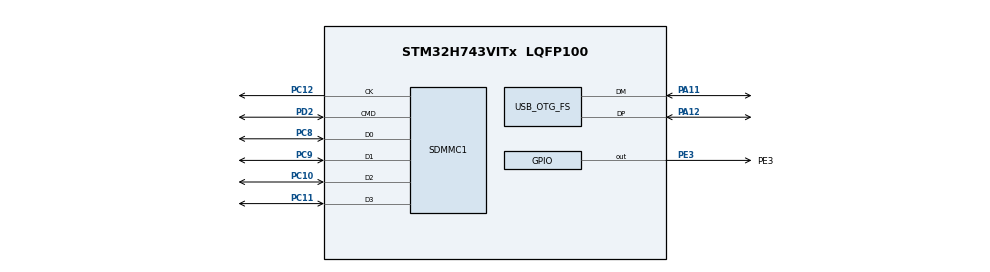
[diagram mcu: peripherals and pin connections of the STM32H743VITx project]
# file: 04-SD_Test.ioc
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Mcu.Family=STM32H7
Mcu.Name=STM32H743VITx
Mcu.Package=LQFP100
NVIC.OTG_FS_IRQn=true\:0\:0\:false\:false\:true\:false\:true\:true
NVIC.PriorityGroup=NVIC_PRIORITYGROUP_4
NVIC.SDMMC1_IRQn=true\:0\:0\:false\:false\:true\:true\:true\:true
PA11.Mode=Device_Only
PA11.Signal=USB_OTG_FS_DM
PA12.Mode=Device_Only
PA12.Signal=USB_OTG_FS_DP
PA13\ (JTMS/SWDIO).Mode=Serial_Wire
PA13\ (JTMS/SWDIO).Signal=DEBUG_JTMS-SWDIO
PA14\ (JTCK/SWCLK).Mode=Serial_Wire
PA14\ (JTCK/SWCLK).Signal=DEBUG_JTCK-SWCLK
PC10.Mode=SD_4_bits_Wide_bus
PC10.Signal=SDMMC1_D2
PC11.Mode=SD_4_bits_Wide_bus
PC11.Signal=SDMMC1_D3
PC12.Mode=SD_4_bits_Wide_bus
PC12.Signal=SDMMC1_CK
PC8.Mode=SD_4_bits_Wide_bus
PC8.Signal=SDMMC1_D0
PC9.Mode=SD_4_bits_Wide_bus
PC9.Signal=SDMMC1_D1
PD2.Mode=SD_4_bits_Wide_bus
PD2.Signal=SDMMC1_CMD
PE3.GPIO_Label=PE3
PE3.Signal=GPIO_Output
PH0-OSC_IN\ (PH0).Mode=HSE-External-Oscillator
PH0-OSC_IN\ (PH0).Signal=RCC_OSC_IN
PH1-OSC_OUT\ (PH1).Mode=HSE-External-Oscillator
PH1-OSC_OUT\ (PH1).Signal=RCC_OSC_OUT
ProjectManager.HeapSize=0x2000
ProjectManager.StackSize=0x2000
ProjectManager.TargetToolchain=STM32CubeIDE
RCC.ADCFreq_Value=75000000
RCC.APB1Freq_Value=120000000
RCC.APB2Freq_Value=120000000
RCC.APB3Freq_Value=120000000
RCC.APB4Freq_Value=120000000
RCC.CortexFreq_Value=240000000
RCC.DIVM1=5
RCC.DIVM2=2
RCC.DIVN1=96
RCC.DIVN2=12
RCC.DIVQ1=10
RCC.DIVR2=1
RCC.HCLKFreq_Value=120000000
RCC.HPRE=RCC_HCLK_DIV2
RCC.HSE_VALUE=25000000
RCC.PLL2FRACN=0
RCC.PLLFRACN=0
RCC.PLLSourceVirtual=RCC_PLLSOURCE_HSE
RCC.SYSCLKFreq_VALUE=240000000
RCC.SYSCLKSource=RCC_SYSCLKSOURCE_PLLCLK
RCC.SupplySource=PWR_LDO_SUPPLY
RCC.USBFreq_Value=48000000
SDMMC1.ClockDiv=2
SDMMC1.TransceiverPresent=SDMMC_TRANSCEIVER_NOT_PRESENT
USB_DEVICE.CLASS_NAME_FS=MSC
USB_DEVICE.MSC_MEDIA_PACKET-MSC_FS=4096
USB_DEVICE.VirtualMode-MSC_FS=Msc
USB_DEVICE.VirtualModeFS=Msc_FS
USB_OTG_FS.VirtualMode=Device_Only
USB_OTG_FS.dma_enable=ENABLE
VP_USB_DEVICE_VS_USB_DEVICE_MSC_FS.Mode=MSC_FS
board=custom

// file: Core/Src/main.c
/* USER CODE BEGIN Header */
/**
  ******************************************************************************
  * @file           : main.c
  * @brief          : Main program body
  ******************************************************************************
  * @attention
  *
  * Copyright (c) 2023 STMicroelectronics.
  * All rights reserved.
  *
  * This software is licensed under terms that can be found in the LICENSE file
  * in the root directory of this software component.
  * If no LICENSE file comes with this software, it is provided AS-IS.
  *
  ******************************************************************************
  */
/* USER CODE END Header */
#include "main.h"
#include "sdmmc.h"
#include "gpio.h"
#include "usb_device.h"

/* USER CODE BEGIN PV */
HAL_SD_CardCIDTypedef pCID;
HAL_SD_CardCSDTypedef pCSD;
HAL_SD_CardInfoTypeDef pCardInfo;
/* USER CODE END PV */

void SystemClock_Config(void);

/* USER CODE BEGIN 0 */

void LED_Blink(uint32_t delay)
{
	HAL_GPIO_WritePin(PE3_GPIO_Port,PE3_Pin,GPIO_PIN_SET);
	HAL_Delay(delay - 1);
	HAL_GPIO_WritePin(PE3_GPIO_Port,PE3_Pin,GPIO_PIN_RESET);
	HAL_Delay(500-1);
}
/* USER CODE END 0 */

int main(void)
{
  /* USER CODE BEGIN 1 */
#ifdef W25Qxx
  SCB->VTOR = QSPI_BASE;
	#endif
//MPU_Config();
//CPU_CACHE_Enable();
  /* USER CODE END 1 */

  /* MCU Configuration--------------------------------------------------------*/

  /* Reset of all peripherals, Initializes the Flash interface and the Systick. */
  HAL_Init();

  /* Configure the system clock */
  SystemClock_Config();

  /* Initialize all configured peripherals */
  MX_GPIO_Init();
  MX_SDMMC1_SD_Init();
  /* USER CODE BEGIN 2 */
  /*
	HAL_SD_GetCardCID(&hsd1, &pCID);
	HAL_SD_GetCardCSD(&hsd1, &pCSD);
	HAL_SD_GetCardInfo(&hsd1, &pCardInfo);

	HAL_Delay(50);
	*/
	MX_USB_DEVICE_Init();
  /* USER CODE END 2 */

  /* Infinite loop */
  while (1)
  {

    /* USER CODE BEGIN 3 */
	  LED_Blink(5);
  }
  /* USER CODE END 3 */
}

void SystemClock_Config(void)
{
  RCC_OscInitTypeDef RCC_OscInitStruct = {0};
  RCC_ClkInitTypeDef RCC_ClkInitStruct = {0};

  /** Supply configuration update enable
  */
  HAL_PWREx_ConfigSupply(PWR_LDO_SUPPLY);

  /** Configure the main internal regulator output voltage
  */
  __HAL_PWR_VOLTAGESCALING_CONFIG(PWR_REGULATOR_VOLTAGE_SCALE2);

  while(!__HAL_PWR_GET_FLAG(PWR_FLAG_VOSRDY)) {}

  /** Initializes the RCC Oscillators according to the specified parameters
  * in the RCC_OscInitTypeDef structure.
  */
  RCC_OscInitStruct.OscillatorType = RCC_OSCILLATORTYPE_HSE;
  RCC_OscInitStruct.HSEState = RCC_HSE_ON;
  RCC_OscInitStruct.PLL.PLLState = RCC_PLL_ON;
  RCC_OscInitStruct.PLL.PLLSource = RCC_PLLSOURCE_HSE;
  RCC_OscInitStruct.PLL.PLLM = 5;
  RCC_OscInitStruct.PLL.PLLN = 96;
  RCC_OscInitStruct.PLL.PLLP = 2;
  RCC_OscInitStruct.PLL.PLLQ = 10;
  RCC_OscInitStruct.PLL.PLLR = 2;
  RCC_OscInitStruct.PLL.PLLRGE = RCC_PLL1VCIRANGE_2;
  RCC_OscInitStruct.PLL.PLLVCOSEL = RCC_PLL1VCOWIDE;
  RCC_OscInitStruct.PLL.PLLFRACN = 0;
  if (HAL_RCC_OscConfig(&RCC_OscInitStruct) != HAL_OK)
  {
    Error_Handler();
  }

  /** Initializes the CPU, AHB and APB buses clocks
  */
  RCC_ClkInitStruct.ClockType = RCC_CLOCKTYPE_HCLK|RCC_CLOCKTYPE_SYSCLK
                              |RCC_CLOCKTYPE_PCLK1|RCC_CLOCKTYPE_PCLK2
                              |RCC_CLOCKTYPE_D3PCLK1|RCC_CLOCKTYPE_D1PCLK1;
  RCC_ClkInitStruct.SYSCLKSource = RCC_SYSCLKSOURCE_PLLCLK;
  RCC_ClkInitStruct.SYSCLKDivider = RCC_SYSCLK_DIV1;
  RCC_ClkInitStruct.AHBCLKDivider = RCC_HCLK_DIV2;
  RCC_ClkInitStruct.APB3CLKDivider = RCC_APB3_DIV1;
  RCC_ClkInitStruct.APB1CLKDivider = RCC_APB1_DIV1;
  RCC_ClkInitStruct.APB2CLKDivider = RCC_APB2_DIV1;
  RCC_ClkInitStruct.APB4CLKDivider = RCC_APB4_DIV1;

  if (HAL_RCC_ClockConfig(&RCC_ClkInitStruct, FLASH_LATENCY_2) != HAL_OK)
  {
    Error_Handler();
  }
}

void Error_Handler(void)
{
  /* USER CODE BEGIN Error_Handler_Debug */
  /* User can add his own implementation to report the HAL error return state */
  __disable_irq();
  while (1)
  {
	  LED_Blink(500);
  }
  /* USER CODE END Error_Handler_Debug */
}
